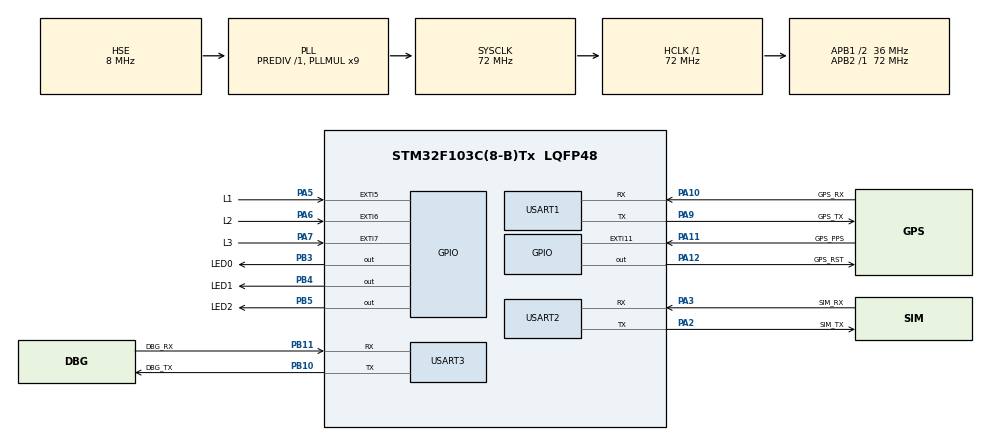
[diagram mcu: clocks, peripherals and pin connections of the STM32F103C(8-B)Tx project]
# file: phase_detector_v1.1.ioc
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Mcu.Family=STM32F1
Mcu.Name=STM32F103C(8-B)Tx
Mcu.Package=LQFP48
NVIC.EXTI15_10_IRQn=true\:0\:0\:false\:false\:true\:true\:true\:true
NVIC.EXTI9_5_IRQn=true\:0\:0\:false\:false\:true\:true\:true\:true
NVIC.PriorityGroup=NVIC_PRIORITYGROUP_4
NVIC.TIM4_IRQn=true\:0\:0\:false\:false\:true\:true\:true\:true
NVIC.USART1_IRQn=true\:0\:0\:false\:false\:true\:true\:true\:true
NVIC.USART2_IRQn=true\:0\:0\:false\:false\:true\:true\:true\:true
PA10.GPIO_Label=GPS_RX
PA10.Mode=Asynchronous
PA10.Signal=USART1_RX
PA11.GPIO_Label=GPS_PPS
PA11.Signal=GPXTI11
PA12.GPIO_Label=GPS_RST
PA12.Signal=GPIO_Output
PA13.Mode=Serial_Wire
PA13.Signal=SYS_JTMS-SWDIO
PA14.Mode=Serial_Wire
PA14.Signal=SYS_JTCK-SWCLK
PA2.GPIO_Label=SIM_TX
PA2.Mode=Asynchronous
PA2.Signal=USART2_TX
PA3.GPIO_Label=SIM_RX
PA3.Mode=Asynchronous
PA3.Signal=USART2_RX
PA5.GPIO_Label=L1
PA5.GPIO_ModeDefaultEXTI=GPIO_MODE_IT_FALLING
PA5.Signal=GPXTI5
PA6.GPIO_Label=L2
PA6.GPIO_ModeDefaultEXTI=GPIO_MODE_IT_FALLING
PA6.Signal=GPXTI6
PA7.GPIO_Label=L3
PA7.GPIO_ModeDefaultEXTI=GPIO_MODE_IT_FALLING
PA7.Signal=GPXTI7
PA9.GPIO_Label=GPS_TX
PA9.Mode=Asynchronous
PA9.Signal=USART1_TX
PB10.GPIO_Label=DBG_TX
PB10.Mode=Asynchronous
PB10.Signal=USART3_TX
PB11.GPIO_Label=DBG_RX
PB11.Mode=Asynchronous
PB11.Signal=USART3_RX
PB3.GPIO_Label=LED0
PB3.PinState=GPIO_PIN_SET
PB3.Signal=GPIO_Output
PB4.GPIO_Label=LED1
PB4.PinState=GPIO_PIN_SET
PB4.Signal=GPIO_Output
PB5.GPIO_Label=LED2
PB5.PinState=GPIO_PIN_SET
PB5.Signal=GPIO_Output
PD0-OSC_IN.Mode=HSE-External-Oscillator
PD0-OSC_IN.Signal=RCC_OSC_IN
PD1-OSC_OUT.Mode=HSE-External-Oscillator
PD1-OSC_OUT.Signal=RCC_OSC_OUT
ProjectManager.HeapSize=0x200
ProjectManager.StackSize=0x400
ProjectManager.TargetToolchain=STM32CubeIDE
RCC.AHBFreq_Value=72000000
RCC.APB1CLKDivider=RCC_HCLK_DIV2
RCC.APB1Freq_Value=36000000
RCC.APB1TimFreq_Value=72000000
RCC.APB2Freq_Value=72000000
RCC.APB2TimFreq_Value=72000000
RCC.HCLKFreq_Value=72000000
RCC.PLLMUL=RCC_PLL_MUL9
RCC.PLLSourceVirtual=RCC_PLLSOURCE_HSE
RCC.SYSCLKFreq_VALUE=72000000
RCC.SYSCLKSource=RCC_SYSCLKSOURCE_PLLCLK
RCC.USBFreq_Value=72000000
TIM4.Period=99
TIM4.Prescaler=71
USART1.VirtualMode=VM_ASYNC
USART2.VirtualMode=VM_ASYNC
USART3.VirtualMode=VM_ASYNC
VP_TIM4_VS_ClockSourceINT.Mode=Internal
board=custom

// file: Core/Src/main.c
/* USER CODE BEGIN Header */
/**
  ******************************************************************************
  * @file           : main.c
  * @brief          : Main program body
  ******************************************************************************
  * @attention
  *
  * Copyright (c) 2023 STMicroelectronics.
  * All rights reserved.
  *
  * This software is licensed under terms that can be found in the LICENSE file
  * in the root directory of this software component.
  * If no LICENSE file comes with this software, it is provided AS-IS.
  *
  ******************************************************************************
  */
/* USER CODE END Header */
#include "main.h"

/* USER CODE BEGIN Includes */
#include "log.h"
/* USER CODE END Includes */

 TIM_HandleTypeDef htim4;

UART_HandleTypeDef huart1;
UART_HandleTypeDef huart2;
UART_HandleTypeDef huart3;

void SystemClock_Config(void);
static void MX_GPIO_Init(void);
static void MX_USART1_UART_Init(void);
static void MX_USART2_UART_Init(void);
static void MX_USART3_UART_Init(void);
static void MX_TIM4_Init(void);
/* USER CODE BEGIN PFP */

extern void appMeasureInit(void) ;
extern void appUartInit(void);
extern void processSimData(void);
/* USER CODE END PFP */

/* USER CODE BEGIN 0 */
int __io_putchar(int ch)
{
  HAL_UART_Transmit(&huart3, (uint8_t *)&ch, 1, 1);
  return ch;
}
/* USER CODE END 0 */

int main(void)
{

  /* MCU Configuration--------------------------------------------------------*/

  /* Reset of all peripherals, Initializes the Flash interface and the Systick. */
  HAL_Init();

  /* Configure the system clock */
  SystemClock_Config();

  /* Initialize all configured peripherals */
  MX_GPIO_Init();
  MX_USART1_UART_Init();
  MX_USART2_UART_Init();
  MX_USART3_UART_Init();
  MX_TIM4_Init();
  /* USER CODE BEGIN 2 */
  Logi("Main app running");
  appMeasureInit();  //Init GPS
  appUartInit();	//Init IRQ UART SIMCOM
  setLedstatus(0, 0, 0);
  /* USER CODE END 2 */

  /* Infinite loop */
  /* USER CODE BEGIN WHILE */
  while (1)
  {
	  processMeasure();
	  processSimData();
    /* USER CODE END WHILE */

  }
}

void SystemClock_Config(void)
{
  RCC_OscInitTypeDef RCC_OscInitStruct = {0};
  RCC_ClkInitTypeDef RCC_ClkInitStruct = {0};

  /** Initializes the RCC Oscillators according to the specified parameters
  * in the RCC_OscInitTypeDef structure.
  */
  RCC_OscInitStruct.OscillatorType = RCC_OSCILLATORTYPE_HSE;
  RCC_OscInitStruct.HSEState = RCC_HSE_ON;
  RCC_OscInitStruct.HSEPredivValue = RCC_HSE_PREDIV_DIV1;
  RCC_OscInitStruct.HSIState = RCC_HSI_ON;
  RCC_OscInitStruct.PLL.PLLState = RCC_PLL_ON;
  RCC_OscInitStruct.PLL.PLLSource = RCC_PLLSOURCE_HSE;
  RCC_OscInitStruct.PLL.PLLMUL = RCC_PLL_MUL9;
  if (HAL_RCC_OscConfig(&RCC_OscInitStruct) != HAL_OK)
  {
    Error_Handler();
  }

  /** Initializes the CPU, AHB and APB buses clocks
  */
  RCC_ClkInitStruct.ClockType = RCC_CLOCKTYPE_HCLK|RCC_CLOCKTYPE_SYSCLK
                              |RCC_CLOCKTYPE_PCLK1|RCC_CLOCKTYPE_PCLK2;
  RCC_ClkInitStruct.SYSCLKSource = RCC_SYSCLKSOURCE_PLLCLK;
  RCC_ClkInitStruct.AHBCLKDivider = RCC_SYSCLK_DIV1;
  RCC_ClkInitStruct.APB1CLKDivider = RCC_HCLK_DIV2;
  RCC_ClkInitStruct.APB2CLKDivider = RCC_HCLK_DIV1;

  if (HAL_RCC_ClockConfig(&RCC_ClkInitStruct, FLASH_LATENCY_2) != HAL_OK)
  {
    Error_Handler();
  }
}

static void MX_TIM4_Init(void)
{

  TIM_ClockConfigTypeDef sClockSourceConfig = {0};
  TIM_MasterConfigTypeDef sMasterConfig = {0};

  htim4.Instance = TIM4;
  htim4.Init.Prescaler = 71;
  htim4.Init.CounterMode = TIM_COUNTERMODE_UP;
  htim4.Init.Period = 99;
  htim4.Init.ClockDivision = TIM_CLOCKDIVISION_DIV1;
  htim4.Init.AutoReloadPreload = TIM_AUTORELOAD_PRELOAD_DISABLE;
  if (HAL_TIM_Base_Init(&htim4) != HAL_OK)
  {
    Error_Handler();
  }
  sClockSourceConfig.ClockSource = TIM_CLOCKSOURCE_INTERNAL;
  if (HAL_TIM_ConfigClockSource(&htim4, &sClockSourceConfig) != HAL_OK)
  {
    Error_Handler();
  }
  sMasterConfig.MasterOutputTrigger = TIM_TRGO_RESET;
  sMasterConfig.MasterSlaveMode = TIM_MASTERSLAVEMODE_DISABLE;
  if (HAL_TIMEx_MasterConfigSynchronization(&htim4, &sMasterConfig) != HAL_OK)
  {
    Error_Handler();
  }

}

static void MX_USART1_UART_Init(void)
{

  huart1.Instance = USART1;
  huart1.Init.BaudRate = 115200;
  huart1.Init.WordLength = UART_WORDLENGTH_8B;
  huart1.Init.StopBits = UART_STOPBITS_1;
  huart1.Init.Parity = UART_PARITY_NONE;
  huart1.Init.Mode = UART_MODE_TX_RX;
  huart1.Init.HwFlowCtl = UART_HWCONTROL_NONE;
  huart1.Init.OverSampling = UART_OVERSAMPLING_16;
  if (HAL_UART_Init(&huart1) != HAL_OK)
  {
    Error_Handler();
  }

}

static void MX_USART2_UART_Init(void)
{

  huart2.Instance = USART2;
  huart2.Init.BaudRate = 115200;
  huart2.Init.WordLength = UART_WORDLENGTH_8B;
  huart2.Init.StopBits = UART_STOPBITS_1;
  huart2.Init.Parity = UART_PARITY_NONE;
  huart2.Init.Mode = UART_MODE_TX_RX;
  huart2.Init.HwFlowCtl = UART_HWCONTROL_NONE;
  huart2.Init.OverSampling = UART_OVERSAMPLING_16;
  if (HAL_UART_Init(&huart2) != HAL_OK)
  {
    Error_Handler();
  }

}

static void MX_USART3_UART_Init(void)
{

  huart3.Instance = USART3;
  huart3.Init.BaudRate = 115200;
  huart3.Init.WordLength = UART_WORDLENGTH_8B;
  huart3.Init.StopBits = UART_STOPBITS_1;
  huart3.Init.Parity = UART_PARITY_NONE;
  huart3.Init.Mode = UART_MODE_TX_RX;
  huart3.Init.HwFlowCtl = UART_HWCONTROL_NONE;
  huart3.Init.OverSampling = UART_OVERSAMPLING_16;
  if (HAL_UART_Init(&huart3) != HAL_OK)
  {
    Error_Handler();
  }

}

static void MX_GPIO_Init(void)
{
  GPIO_InitTypeDef GPIO_InitStruct = {0};

  /* GPIO Ports Clock Enable */
  __HAL_RCC_GPIOD_CLK_ENABLE();
  __HAL_RCC_GPIOA_CLK_ENABLE();
  __HAL_RCC_GPIOB_CLK_ENABLE();

  /*Configure GPIO pin Output Level */
  HAL_GPIO_WritePin(GPS_RST_GPIO_Port, GPS_RST_Pin, GPIO_PIN_RESET);

  /*Configure GPIO pin Output Level */
  HAL_GPIO_WritePin(GPIOB, LED0_Pin|LED1_Pin|LED2_Pin, GPIO_PIN_SET);

  /*Configure GPIO pins : L1_Pin L2_Pin L3_Pin */
  GPIO_InitStruct.Pin = L1_Pin|L2_Pin|L3_Pin;
  GPIO_InitStruct.Mode = GPIO_MODE_IT_FALLING;
  GPIO_InitStruct.Pull = GPIO_NOPULL;
  HAL_GPIO_Init(GPIOA, &GPIO_InitStruct);

  /*Configure GPIO pin : GPS_PPS_Pin */
  GPIO_InitStruct.Pin = GPS_PPS_Pin;
  GPIO_InitStruct.Mode = GPIO_MODE_IT_RISING;
  GPIO_InitStruct.Pull = GPIO_NOPULL;
  HAL_GPIO_Init(GPS_PPS_GPIO_Port, &GPIO_InitStruct);

  /*Configure GPIO pin : GPS_RST_Pin */
  GPIO_InitStruct.Pin = GPS_RST_Pin;
  GPIO_InitStruct.Mode = GPIO_MODE_OUTPUT_PP;
  GPIO_InitStruct.Pull = GPIO_NOPULL;
  GPIO_InitStruct.Speed = GPIO_SPEED_FREQ_LOW;
  HAL_GPIO_Init(GPS_RST_GPIO_Port, &GPIO_InitStruct);

  /*Configure GPIO pins : LED0_Pin LED1_Pin LED2_Pin */
  GPIO_InitStruct.Pin = LED0_Pin|LED1_Pin|LED2_Pin;
  GPIO_InitStruct.Mode = GPIO_MODE_OUTPUT_PP;
  GPIO_InitStruct.Pull = GPIO_NOPULL;
  GPIO_InitStruct.Speed = GPIO_SPEED_FREQ_LOW;
  HAL_GPIO_Init(GPIOB, &GPIO_InitStruct);

  /* EXTI interrupt init*/
  HAL_NVIC_SetPriority(EXTI9_5_IRQn, 0, 0);
  HAL_NVIC_EnableIRQ(EXTI9_5_IRQn);

  HAL_NVIC_SetPriority(EXTI15_10_IRQn, 0, 0);
  HAL_NVIC_EnableIRQ(EXTI15_10_IRQn);

}

void Error_Handler(void)
{
  __disable_irq();
  while (1)
  {
  }
}
